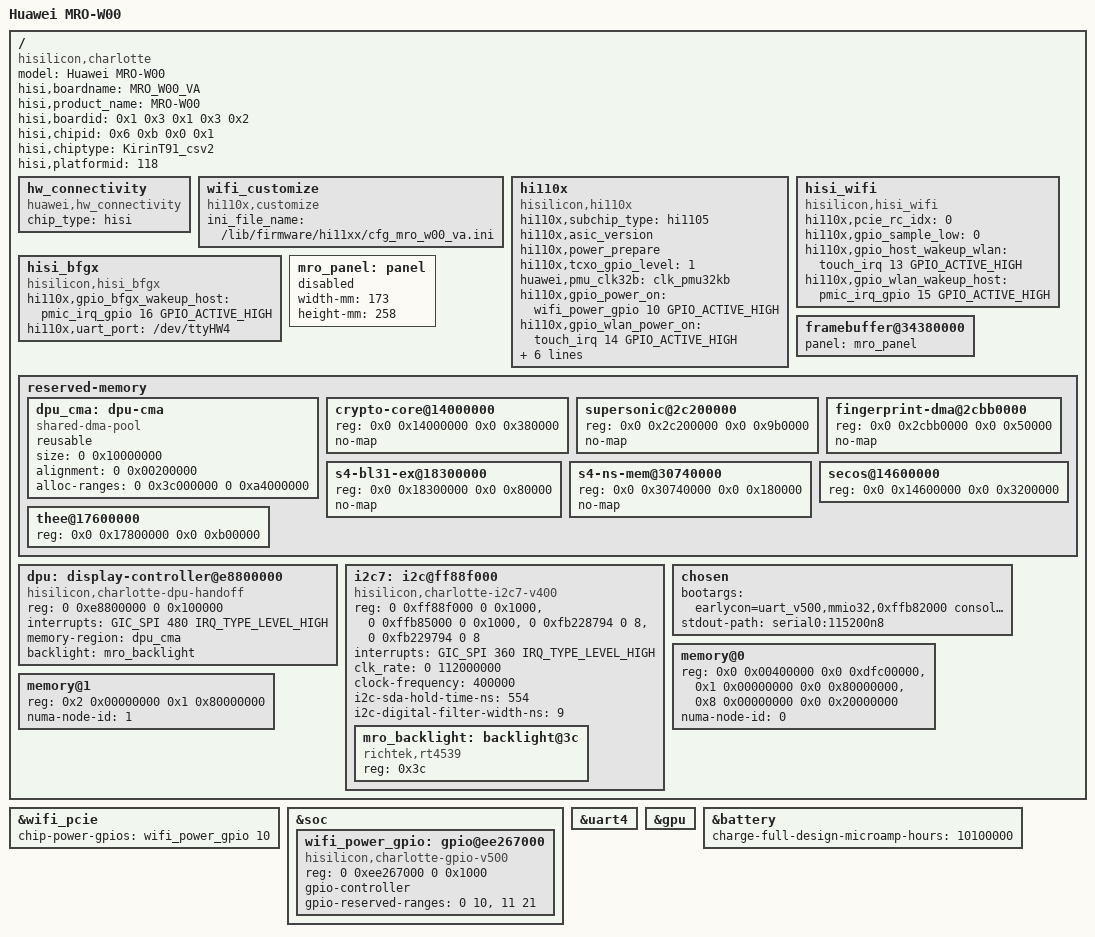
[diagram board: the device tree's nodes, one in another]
// SPDX-License-Identifier: GPL-2.0
/*
 * Huawei MRO-W00, Hisilicon Kirin 9010W (charlotte)
 *
 * MRO-W00 is the Kirin 9010W variant of the 12.2-inch MatePad Pro board
 * family.  The SoC-internal blocks, UART, PCIe/WiFi, UFS, USB and display
 * handoff are shared with TGR-W00; only board identity, battery capacity
 * and the WiFi calibration file differ.
 */

/dts-v1/;

#include "charlotte.dtsi"

&wifi_pcie {
	status = "okay";
	/* Stock MRO-W00 drives the Hi1105 main rail from bank 3 pin 10. */
	chip-power-gpios = <&wifi_power_gpio 10 GPIO_ACTIVE_HIGH>;
};

&soc {
	/* Hi1105 chip power enable.  The live MRO-W00 tree exposes only
	 * line 10 of this bank; every other line stays firmware-owned.
	 */
	wifi_power_gpio: gpio@ee267000 {
		compatible = "hisilicon,charlotte-gpio-v500";
		reg = <0 0xee267000 0 0x1000>;
		gpio-controller;
		#gpio-cells = <2>;
		gpio-reserved-ranges = <0 10>, <11 21>;
	};
};

&uart4 {
	status = "okay";
};

&gpu {
	status = "okay";
};

/* MRO-W00 uses the 10100 mAh dual-cell pack. */
&battery {
	charge-full-design-microamp-hours = <10100000>;
};

/ {
	model = "Huawei MRO-W00";
	compatible = "hisilicon,charlotte";
	hisi,boardname = "MRO_W00_VA";
	hisi,product_name = "MRO-W00";
	hisi,boardid = <0x1 0x3 0x1 0x3 0x2>;
	hisi,chipid = <0x6 0xb 0x0 0x1>;
	hisi,chiptype = "KirinT91_csv2";
	hisi,platformid = "118";

	hw_connectivity {
		compatible = "huawei,hw_connectivity";
		chip_type = "hisi";
	};

	wifi_customize {
		compatible = "hi110x,customize";
		ini_file_name = "/lib/firmware/hi11xx/cfg_mro_w00_va.ini";
	};

	hi110x {
		compatible = "hisilicon,hi110x", "hisilicon,hi1102";
		hi110x,subchip_type = "hi1105";
		hi110x,asic_version;
		hi110x,power_prepare;
		hi110x,tcxo_gpio_level = <1>;
		huawei,pmu_clk32b = "clk_pmu32kb";
		hi110x,gpio_power_on = <&wifi_power_gpio 10 GPIO_ACTIVE_HIGH>;
		hi110x,gpio_wlan_power_on = <&touch_irq 14 GPIO_ACTIVE_HIGH>;
		hi110x,gpio_bfgx_power_on = <&wifi_gpio 5 GPIO_ACTIVE_HIGH>;
		hi110x,gpio_ssi_clk = <&wifi_gpio 7 GPIO_ACTIVE_HIGH>;
		hi110x,gpio_ssi_data = <&wifi_gpio 8 GPIO_ACTIVE_HIGH>;
	};

	hisi_wifi {
		compatible = "hisilicon,hisi_wifi";
		hi110x,pcie_rc_idx = <0>;
		hi110x,gpio_sample_low = <0>;
		hi110x,gpio_host_wakeup_wlan = <&touch_irq 13 GPIO_ACTIVE_HIGH>;
		hi110x,gpio_wlan_wakeup_host = <&pmic_irq_gpio 15 GPIO_ACTIVE_HIGH>;
	};

	hisi_bfgx {
		compatible = "hisilicon,hisi_bfgx";
		hi110x,gpio_bfgx_wakeup_host = <&pmic_irq_gpio 16 GPIO_ACTIVE_HIGH>;
		hi110x,uart_port = "/dev/ttyHW4";
	};

	/* Physical panel metadata for the shared 12.2-inch 3:2 panel.
	 * The display hardware remains owned by the firmware handoff.
	 */
	mro_panel: panel {
		/* Metadata only: no autonomous panel driver is available yet.
		 * Prevent fw_devlink waiting for a supplier that will not bind.
		 */
		status = "disabled";
		width-mm = <173>;
		height-mm = <258>;
	};

	framebuffer@34380000 {
		panel = <&mro_panel>;
	};

	reserved-memory {
		/* Reusable scanout allocations, independent of the general 32 MiB
		 * CMA pool. Keep DMA below 4 GiB for the handoff diagnostic stage.
		 */
		dpu_cma: dpu-cma {
			compatible = "shared-dma-pool";
			reusable;
			/* Login greeter and user compositor can each keep three
			 * full-size BOs alive during the session transition.
			 */
			size = <0 0x10000000>;
			alignment = <0 0x00200000>;
			alloc-ranges = <0 0x3c000000 0 0xa4000000>;
		};

		/* MRO-W00 secure firmware layout from the live MRO FDT.  The
		 * shared SoC dtsi still carries the TGR-W00 addresses.
		 */
		crypto-core@14000000 {
			reg = <0x0 0x14000000 0x0 0x380000>;
			no-map;
		};

		supersonic@2c200000 {
			reg = <0x0 0x2c200000 0x0 0x9b0000>;
			no-map;
		};

		fingerprint-dma@2cbb0000 {
			reg = <0x0 0x2cbb0000 0x0 0x50000>;
			no-map;
		};

		s4-bl31-ex@18300000 {
			reg = <0x0 0x18300000 0x0 0x80000>;
			no-map;
		};

		s4-ns-mem@30740000 {
			reg = <0x0 0x30740000 0x0 0x180000>;
			no-map;
		};

		/* Live MRO FDT places secure OS at 0x14600000+0x3200000 and
		 * TEE at 0x17800000+0xb00000.
		 */
		secos@14600000 {
			reg = <0x0 0x14600000 0x0 0x3200000>;
		};

		thee@17600000 {
			reg = <0x0 0x17800000 0x0 0xb00000>;
		};
	};

	/* E880 DPU/DSI0 instance and SPI 480 are present together in the
	 * stock composer_manager and dsi@E8800000 nodes (not the E890 DPU).
	 * probe_only=1 retains simpledrm for explicit bounded diagnostics.
	 */
	dpu: display-controller@e8800000 {
		compatible = "hisilicon,charlotte-dpu-handoff";
		reg = <0 0xe8800000 0 0x100000>;
		interrupts = <GIC_SPI 480 IRQ_TYPE_LEVEL_HIGH>;
		memory-region = <&dpu_cma>;
		backlight = <&mro_backlight>;
	};

	/* Stock TGR backlight bus; reset bit14/gate bit31 and GPIO230/231.
	 * LED on/off retains the firmware's brightness and IC setup.
	 */
	i2c7: i2c@ff88f000 {
		compatible = "hisilicon,charlotte-i2c7-v400";
		reg = <0 0xff88f000 0 0x1000>,
		      <0 0xffb85000 0 0x1000>,
		      <0 0xfb228794 0 8>,
		      <0 0xfb229794 0 8>;
		reg-names = "controller", "crg", "iomux", "pad";
		interrupts = <GIC_SPI 360 IRQ_TYPE_LEVEL_HIGH>;
		clk_rate = <0 112000000>;
		clock-frequency = <400000>;
		i2c-sda-hold-time-ns = <554>;
		i2c-digital-filter-width-ns = <9>;
		#address-cells = <1>;
		#size-cells = <0>;
		mro_backlight: backlight@3c {
			compatible = "richtek,rt4539";
			reg = <0x3c>;
		};
	};

	chosen {
		bootargs = "earlycon=uart_v500,mmio32,0xffb82000 console=ttyHW0,115200 console=tty0 ignore_loglevel loglevel=8 nokaslr";
		stdout-path = "serial0:115200n8";
	};

	/* Live MRO-W00 (12 GiB) FDT: one NUMA node below 4 GiB plus the
	 * 32-32.5 GiB bank, and a second node for 8-14 GiB.  Keep the first
	 * 4 MiB out of the usable map; the firmware reservations in the SoC
	 * dtsi cover the rest of the holes.
	 */
	memory@0 {
		device_type = "memory";
		reg = <0x0 0x00400000 0x0 0xdfc00000>,
		      <0x1 0x00000000 0x0 0x80000000>,
		      <0x8 0x00000000 0x0 0x20000000>;
		numa-node-id = <0>;
	};

	memory@1 {
		device_type = "memory";
		reg = <0x2 0x00000000 0x1 0x80000000>;
		numa-node-id = <1>;
	};
};
